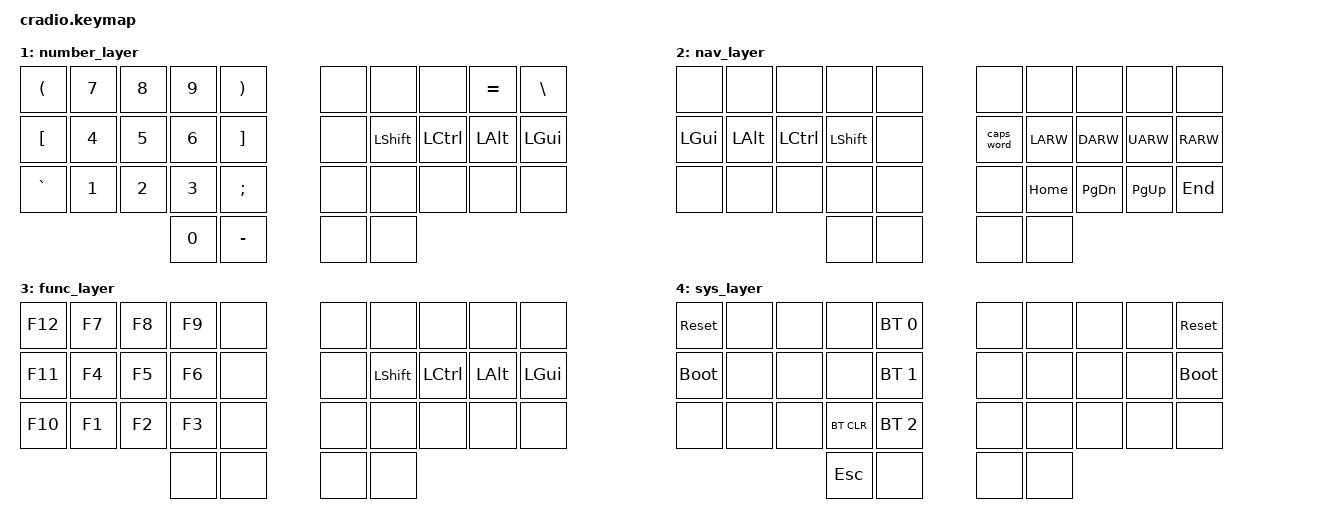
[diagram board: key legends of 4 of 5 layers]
// Copyright (c) 2022 The ZMK Contributors
// SPDX-License-Identifier: MIT

#include <behaviors.dtsi>
#include <dt-bindings/zmk/keys.h>
#include <dt-bindings/zmk/bt.h>

// Home row mods macro
#define GACS(k1,k2,k3,k4)   &hm LGUI k1     &hm LALT k2     &hm LCTRL k3    &hm LSHFT k4
#define SCAG(k1,k2,k3,k4)   &hm RSHFT k1    &hm RCTRL k2    &hm RALT k3     &hm RGUI k4

/ {
    behaviors {
        hm: homerow_mods {
            compatible = "zmk,behavior-hold-tap";
            label = "HOMEROW_MODS";
            #binding-cells = <2>;
            tapping-term-ms = <150>;
            quick-tap-ms = <0>;
            flavor = "tap-preferred";
            bindings = <&kp>, <&kp>;
        };
    };

    combos {
        compatible = "zmk,combos";
        combo_del {
            timeout-ms = <50>;
            key-positions = <32 33>;
            bindings = <&kp DEL>;
        };
    };

    keymap {
        compatible = "zmk,keymap";
        default_layer {
            bindings = <
                &kp Q       &kp W       &kp F       &kp P       &kp B           &kp J       &kp L       &kp U       &kp Y       &kp SQT
                GACS(A,         R,          S,          T)      &kp G           &kp M       SCAG(N,         E,          I,          O)
                &kp Z       &kp X       &kp C       &kp D       &kp V           &kp K       &kp H       &kp COMMA   &kp DOT     &kp FSLH
                                                    &lt 2 SPACE &lt 4 TAB       &lt 3 ENTER &lt 1 BSPC
            >;
        };

        number_layer {
            bindings = <
                &kp LPAR    &kp N7      &kp N8      &kp N9      &kp RPAR        &none       &none       &none       &kp EQUAL   &kp BSLH
                &kp LBKT    &kp N4      &kp N5      &kp N6      &kp RBKT        &none       &kp LSHFT   &kp LCTRL   &kp LALT    &kp LGUI
                &kp GRAVE   &kp N1      &kp N2      &kp N3      &kp SEMI        &none       &none       &none       &none       &none
                                                    &kp N0      &kp MINUS       &none       &none
            >;
        };

        nav_layer {
            bindings = <
                &none       &none       &none       &none       &none           &none       &none       &none       &none       &none
                &kp LGUI    &kp LALT    &kp LCTRL   &kp LSHIFT  &none           &caps_word  &kp LARW    &kp DARW    &kp UARW    &kp RARW
                &none       &none       &none       &none       &none           &none       &kp HOME    &kp PG_DN   &kp PG_UP   &kp END
                                                    &none       &none           &none       &none
            >;
        };

        func_layer {
            bindings = <
                &kp F12     &kp F7      &kp F8      &kp F9      &none           &none       &none       &none       &none       &none
                &kp F11     &kp F4      &kp F5      &kp F6      &none           &none       &kp LSHFT   &kp LCTRL   &kp LALT    &kp LGUI
                &kp F10     &kp F1      &kp F2      &kp F3      &none           &none       &none       &none       &none       &none
                                                    &none       &none           &none       &none
            >;
        };

        sys_layer {
            bindings = <
                &sys_reset  &none       &none       &none       &bt BT_SEL 0    &none       &none       &none       &none       &sys_reset
                &bootloader &none       &none       &none       &bt BT_SEL 1    &none       &none       &none       &none       &bootloader
                &none       &none       &none       &bt BT_CLR  &bt BT_SEL 2    &none       &none       &none       &none       &none
                                                    &kp ESC     &none           &none       &none
            >;
        };
    };
};
